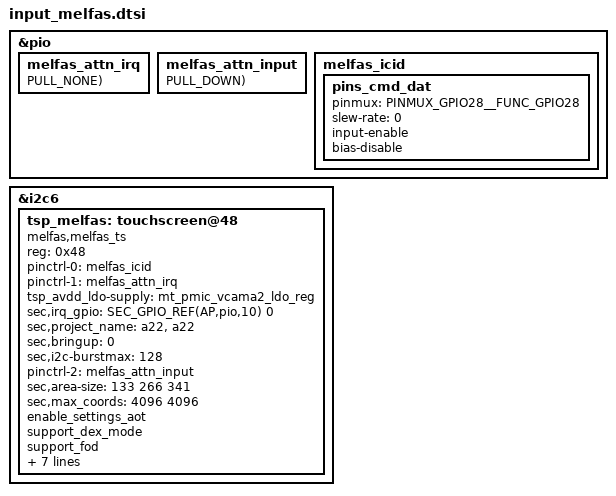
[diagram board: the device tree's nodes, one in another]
&pio {
	melfas_attn_irq: melfas_attn_irq {
		GPIO_CONFIG_PUD(AP,pio,10, FUNC_INPUT_WAKEUP, PULL_NONE);
	};

	melfas_attn_input: melfas_attn_input {
		GPIO_CONFIG_PUD(AP,pio,10, FUNC_INPUT, PULL_DOWN);
	};
};

&i2c6 {
	#address-cells = <1>;
	#size-cells = <0>;
	status = "ok";
	tsp_melfas: touchscreen@48 {
		status = "ok";
		compatible = "melfas,melfas_ts";
		reg = <0x48>;
		pinctrl-names = "on_state", "off_state";
		pinctrl-0 = <&melfas_attn_irq>;
		pinctrl-1 = <&melfas_attn_input>;
		tsp_avdd_ldo-supply = <&mt_pmic_vcama2_ldo_reg>;
		sec,irq_gpio = <SEC_GPIO_REF(AP,pio,10) 0>;
		
		/* This part is for firmware */
		sec,project_name = "a22", "a22";
		sec,bringup = <0>;
		sec,i2c-burstmax = <128>;
	};
};


/* /home/dpi/qb5_8814/workspace/P4_1716/android/kernel/kmodule/input/sec_input/touchscreen/melfas/dts/input-mtk-tsp-melfas.a22.dtsi */
&pio {
	melfas_icid: melfas_icid {
		pins_cmd_dat {
			pinmux = <PINMUX_GPIO28__FUNC_GPIO28>;
			slew-rate = <0>;
			input-enable;
			bias-disable;
		};
	};
};

&tsp_melfas {
	pinctrl-names = "default", "on_state", "off_state";
	pinctrl-0 = <&melfas_icid>;
	pinctrl-1 = <&melfas_attn_irq>;
	pinctrl-2 = <&melfas_attn_input>;
	sec,area-size = <133 266 341>; /* indicator: 24dp navigator:48dp edge:60px dpi=320 */
	sec,max_coords = <4096 4096>; /* x y */
	enable_settings_aot;
	support_dex_mode;
	support_fod;
	support_fod_lp_mode;
	support_ear_detect_mode;
	//sync-reportrate-120;
	support_open_short_test;
	sec,regulator_boot_on;
	sec,firmware_name = "tsp_melfas/mss100_a22_old.bin";
	sec,tsp-icid_gpio = <&pio 28 0>;
	sec,icid_match_value = <1>;
};

/* /home/dpi/qb5_8814/workspace/P4_1716/android/kernel/kmodule/input/sec_input/touchscreen/melfas/dts/input-mtk-tsp-melfas.a22.02.dtsi */
&tsp_melfas {
	sec,firmware_name = "tsp_melfas/mss100_a22.bin";
};
